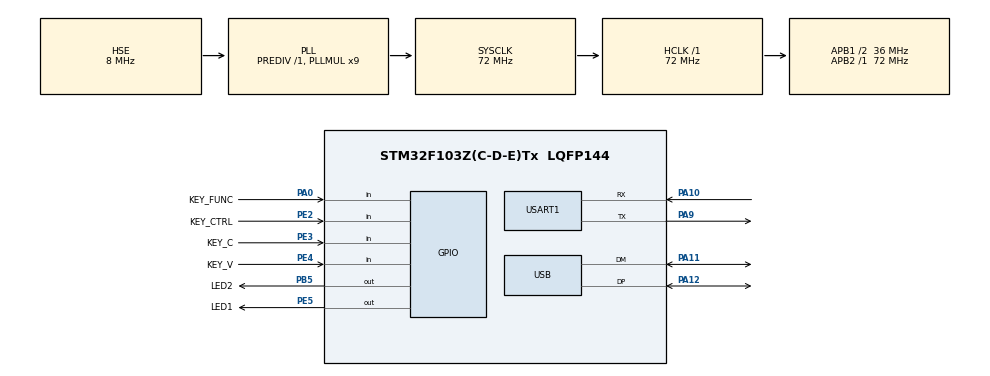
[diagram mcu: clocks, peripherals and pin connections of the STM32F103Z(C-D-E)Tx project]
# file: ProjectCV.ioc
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Mcu.Family=STM32F1
Mcu.Name=STM32F103Z(C-D-E)Tx
Mcu.Package=LQFP144
NVIC.PriorityGroup=NVIC_PRIORITYGROUP_4
NVIC.USB_LP_CAN1_RX0_IRQn=true\:0\:0\:false\:false\:true\:false\:true\:true
OSC_IN.Mode=HSE-External-Oscillator
OSC_IN.Signal=RCC_OSC_IN
OSC_OUT.Mode=HSE-External-Oscillator
OSC_OUT.Signal=RCC_OSC_OUT
PA0-WKUP.GPIO_Label=KEY_FUNC
PA0-WKUP.GPIO_PuPd=GPIO_PULLDOWN
PA0-WKUP.Signal=GPIO_Input
PA10.Mode=Asynchronous
PA10.Signal=USART1_RX
PA11.Mode=Device
PA11.Signal=USB_DM
PA12.Mode=Device
PA12.Signal=USB_DP
PA9.Mode=Asynchronous
PA9.Signal=USART1_TX
PB5.GPIO_Label=LED2
PB5.Signal=GPIO_Output
PE2.GPIO_Label=KEY_CTRL
PE2.GPIO_PuPd=GPIO_PULLUP
PE2.Signal=GPIO_Input
PE3.GPIO_Label=KEY_C
PE3.GPIO_PuPd=GPIO_PULLUP
PE3.Signal=GPIO_Input
PE4.GPIO_Label=KEY_V
PE4.GPIO_PuPd=GPIO_PULLUP
PE4.Signal=GPIO_Input
PE5.GPIO_Label=LED1
PE5.Signal=GPIO_Output
ProjectManager.HeapSize=0x200
ProjectManager.StackSize=0x400
ProjectManager.TargetToolchain=STM32CubeIDE
RCC.AHBFreq_Value=72000000
RCC.APB1CLKDivider=RCC_HCLK_DIV2
RCC.APB1Freq_Value=36000000
RCC.APB1TimFreq_Value=72000000
RCC.APB2Freq_Value=72000000
RCC.APB2TimFreq_Value=72000000
RCC.HCLKFreq_Value=72000000
RCC.PLLMUL=RCC_PLL_MUL9
RCC.PLLSourceVirtual=RCC_PLLSOURCE_HSE
RCC.SYSCLKFreq_VALUE=72000000
RCC.SYSCLKSource=RCC_SYSCLKSOURCE_PLLCLK
RCC.USBFreq_Value=48000000
RCC.USBPrescaler=RCC_USBCLKSOURCE_PLL_DIV1_5
USART1.VirtualMode=VM_ASYNC
USB_DEVICE.CLASS_NAME_FS=CUSTOM_HID
USB_DEVICE.MANUFACTURER_STRING=ProjectCV
USB_DEVICE.PID_CUSTOMHID_FS=0x0923
USB_DEVICE.PRODUCT_STRING_CUSTOMHID_FS=ProjectCV Keyboard
USB_DEVICE.VID=0x2022
USB_DEVICE.VirtualMode=CustomHid
USB_DEVICE.VirtualModeFS=Custom_Hid_FS
VP_SYS_VS_ND.Mode=No_Debug
VP_USB_DEVICE_VS_USB_DEVICE_CUSTOM_HID_FS.Mode=CUSTOM_HID_FS
board=custom

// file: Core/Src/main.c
/* USER CODE BEGIN Header */
/**
  ******************************************************************************
  * @file           : main.c
  * @brief          : Main program body
  ******************************************************************************
  * @attention
  *
  * Copyright (c) 2022 STMicroelectronics.
  * All rights reserved.
  *
  * This software is licensed under terms that can be found in the LICENSE file
  * in the root directory of this software component.
  * If no LICENSE file comes with this software, it is provided AS-IS.
  *
  ******************************************************************************
  */
/* USER CODE END Header */
#include "main.h"
#include "usart.h"
#include "usb_device.h"
#include "gpio.h"

void SystemClock_Config(void);

int main(void)
{

  /* MCU Configuration--------------------------------------------------------*/

  /* Reset of all peripherals, Initializes the Flash interface and the Systick. */
  HAL_Init();

  /* Configure the system clock */
  SystemClock_Config();

  /* Initialize all configured peripherals */
  MX_GPIO_Init();
  MX_USB_DEVICE_Init();
  MX_USART1_UART_Init();
    /* USER CODE BEGIN 2 */
    uint8_t keyCtrlTouch, keyCTouch, keyVTouch, keyFuncTouch;
    uint8_t led1Off, led2Off;
    uint8_t buff[8] = {0x00, 0x00, 0x00, 0x00,0x00, 0x00, 0x00, 0x00};

    HAL_GPIO_WritePin(LED2_GPIO_Port,LED2_Pin,GPIO_PIN_SET);
    /* USER CODE END 2 */

    /* Infinite loop */
    while (1)
    {
        // 获取按键状态
        keyCtrlTouch = !HAL_GPIO_ReadPin(KEY_CTRL_GPIO_Port, KEY_CTRL_Pin);
        keyCTouch = !HAL_GPIO_ReadPin(KEY_C_GPIO_Port, KEY_C_Pin);
        keyVTouch = !HAL_GPIO_ReadPin(KEY_V_GPIO_Port, KEY_V_Pin);
        keyFuncTouch = HAL_GPIO_ReadPin(KEY_FUNC_GPIO_Port, KEY_FUNC_Pin);

        // 通过LED1进行按键测试
        led1Off = keyCtrlTouch || keyCTouch || keyVTouch || keyFuncTouch;

        if(led1Off){
            HAL_GPIO_WritePin(LED1_GPIO_Port,LED1_Pin,GPIO_PIN_SET);
            buff[0] = 0x19;
            buff[1] = 0xe0;
            printf("abc");
        } else {
            HAL_GPIO_WritePin(LED1_GPIO_Port,LED1_Pin,GPIO_PIN_RESET);
            buff[0] = 0x00;
            buff[1] = 0x00;
        }
//      while(USBD_HID_SendReport(&hUsbDeviceFS, buff, 8));
//      USBD_HID_SendReport(&hUsbDeviceFS, buff, 8);
//      HAL_Delay(15);
    }
}

void SystemClock_Config(void)
{
  RCC_OscInitTypeDef RCC_OscInitStruct = {0};
  RCC_ClkInitTypeDef RCC_ClkInitStruct = {0};
  RCC_PeriphCLKInitTypeDef PeriphClkInit = {0};

  /** Initializes the RCC Oscillators according to the specified parameters
  * in the RCC_OscInitTypeDef structure.
  */
  RCC_OscInitStruct.OscillatorType = RCC_OSCILLATORTYPE_HSE;
  RCC_OscInitStruct.HSEState = RCC_HSE_ON;
  RCC_OscInitStruct.HSEPredivValue = RCC_HSE_PREDIV_DIV1;
  RCC_OscInitStruct.HSIState = RCC_HSI_ON;
  RCC_OscInitStruct.PLL.PLLState = RCC_PLL_ON;
  RCC_OscInitStruct.PLL.PLLSource = RCC_PLLSOURCE_HSE;
  RCC_OscInitStruct.PLL.PLLMUL = RCC_PLL_MUL9;
  if (HAL_RCC_OscConfig(&RCC_OscInitStruct) != HAL_OK)
  {
    Error_Handler();
  }

  /** Initializes the CPU, AHB and APB buses clocks
  */
  RCC_ClkInitStruct.ClockType = RCC_CLOCKTYPE_HCLK|RCC_CLOCKTYPE_SYSCLK
                              |RCC_CLOCKTYPE_PCLK1|RCC_CLOCKTYPE_PCLK2;
  RCC_ClkInitStruct.SYSCLKSource = RCC_SYSCLKSOURCE_PLLCLK;
  RCC_ClkInitStruct.AHBCLKDivider = RCC_SYSCLK_DIV1;
  RCC_ClkInitStruct.APB1CLKDivider = RCC_HCLK_DIV2;
  RCC_ClkInitStruct.APB2CLKDivider = RCC_HCLK_DIV1;

  if (HAL_RCC_ClockConfig(&RCC_ClkInitStruct, FLASH_LATENCY_2) != HAL_OK)
  {
    Error_Handler();
  }
  PeriphClkInit.PeriphClockSelection = RCC_PERIPHCLK_USB;
  PeriphClkInit.UsbClockSelection = RCC_USBCLKSOURCE_PLL_DIV1_5;
  if (HAL_RCCEx_PeriphCLKConfig(&PeriphClkInit) != HAL_OK)
  {
    Error_Handler();
  }
}

void Error_Handler(void)
{
  __disable_irq();
  while (1)
  {
  }
}
